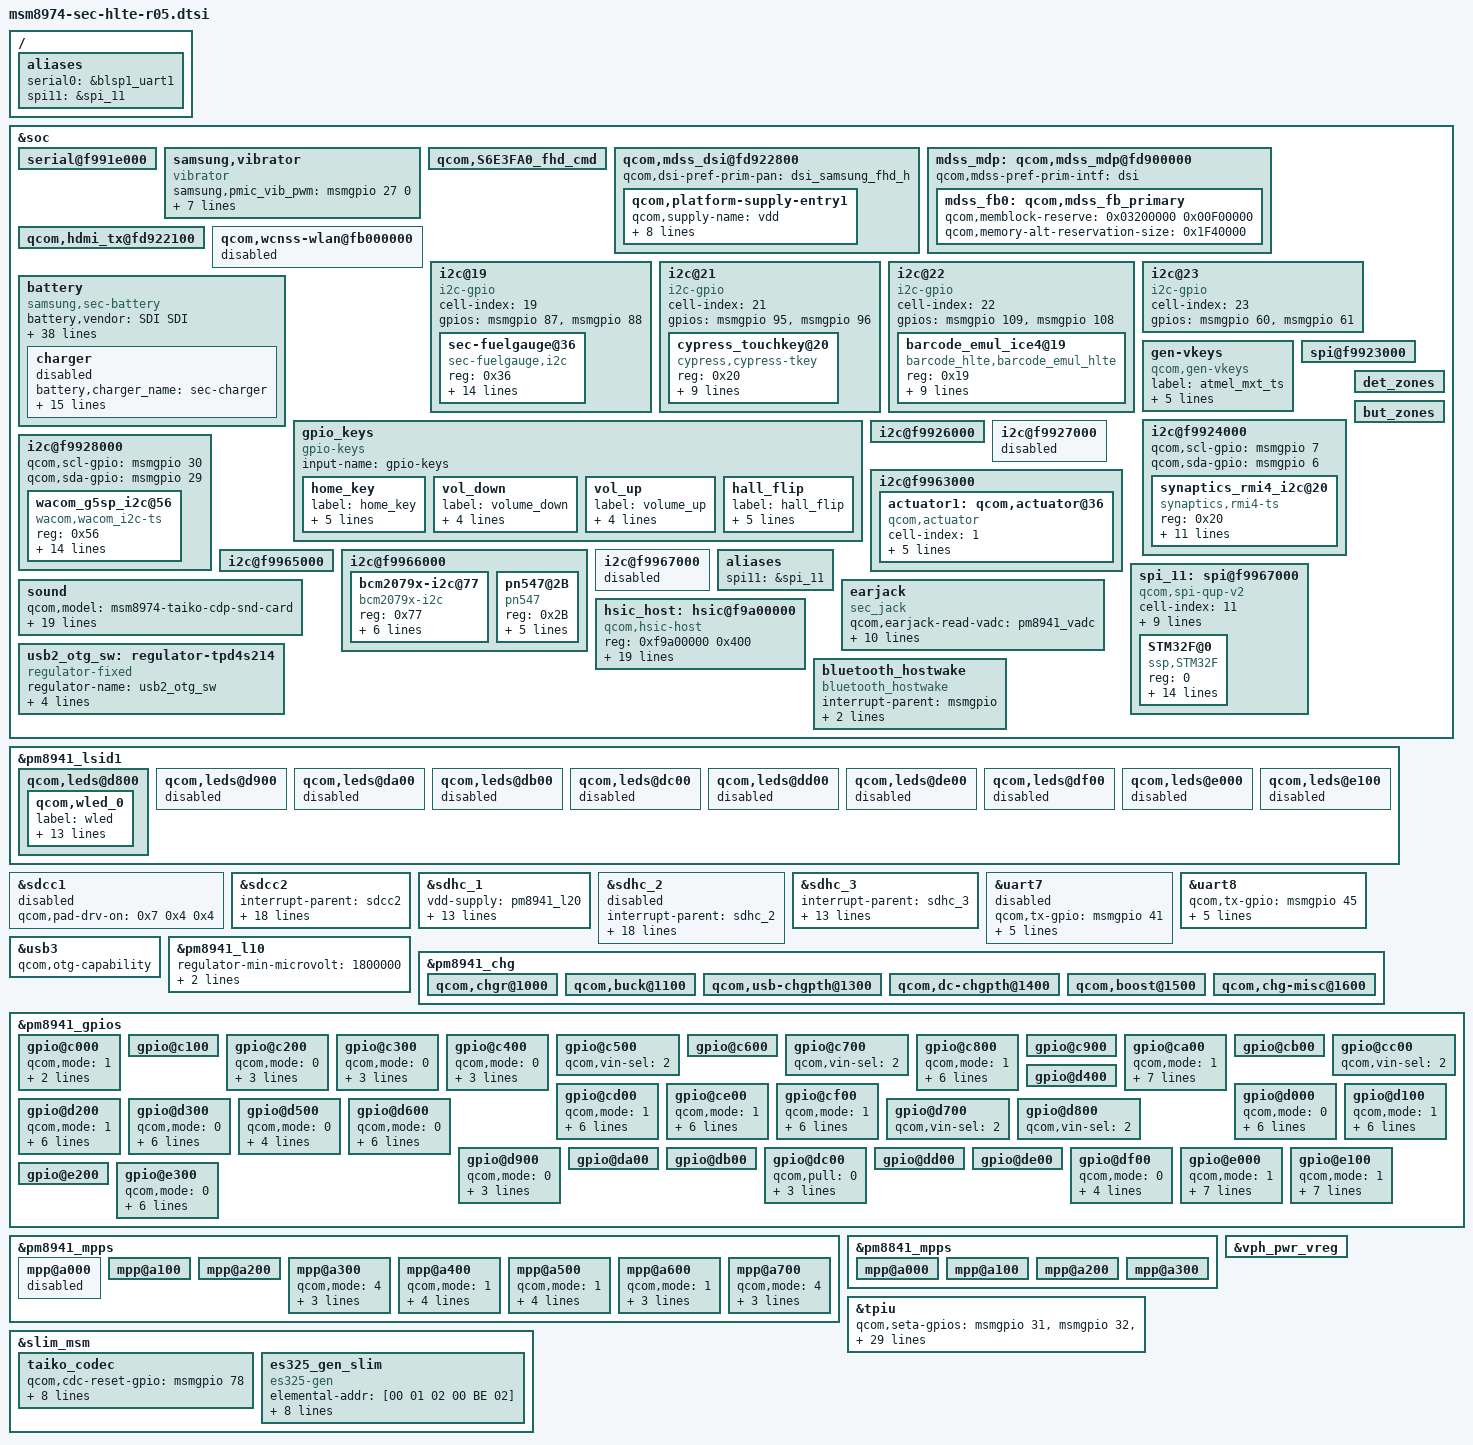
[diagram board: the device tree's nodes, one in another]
/* Copyright (c) 2012-2013, The Linux Foundation. All rights reserved.
 *
 * This program is free software; you can redistribute it and/or modify
 * it under the terms of the GNU General Public License version 2 and
 * only version 2 as published by the Free Software Foundation.
 *
 * This program is distributed in the hope that it will be useful,
 * but WITHOUT ANY WARRANTY; without even the implied warranty of
 * MERCHANTABILITY or FITNESS FOR A PARTICULAR PURPOSE.  See the
 * GNU General Public License for more details.
 */

/include/ "msm8974-leds.dtsi"
/include/ "msm8974-camera-sensor-hlte-r02.dtsi"
/include/ "msm8974-sii8240_mhl-hlte-r05.dtsi"
/include/ "msm8974-max77803-hlte-r02.dtsi"
/include/ "msm8974-w1.dtsi"

/ {
	aliases {
		serial0 = &blsp1_uart1;
		spi11 = &spi_11;
	};
};

&soc {
	serial@f991e000 {
		status = "ok";
	};

	samsung,vibrator {
		compatible = "vibrator";
		samsung,pmic_vib_pwm = <&msmgpio 27 0>;
		samsung,pmic_vib_pwm_jpn = <&msmgpio 59 0>;
		samsung,vib_model = <1>;
		samsung,pmic_vib_en = <0>;
		samsung,pmic_haptic_pwr_en = <0>;
		samsung,is_pmic_vib_pwm = <0>;
		samsung,pwm_period_us = <40>;
		samsung,duty_us = <36>;
		status = "ok";
	};
	qcom,S6E3FA0_fhd_cmd  {
		status = "ok";
	};

	qcom,mdss_dsi@fd922800 {
		qcom,dsi-pref-prim-pan = <&dsi_samsung_fhd_h>;
		qcom,platform-supply-entry1 {
				qcom,supply-name = "vdd";
				qcom,supply-min-voltage = <3000000>;
				qcom,supply-max-voltage = <3000000>;
				qcom,supply-enable-load = <100000>;
				qcom,supply-disable-load = <100>;
				qcom,supply-pre-on-sleep = <0>;
				qcom,supply-post-on-sleep = <20>;
				qcom,supply-pre-off-sleep = <0>;
				qcom,supply-post-off-sleep = <0>;
		};
	};

	mdss_mdp: qcom,mdss_mdp@fd900000 {
		qcom,mdss-pref-prim-intf = "dsi";
		mdss_fb0: qcom,mdss_fb_primary {
		    qcom,memblock-reserve = <0x03200000 0x00F00000>;
			qcom,memory-alt-reservation-size = <0x1F40000>;	 /* Framebuffer reservation only for LPM or recovery boot mode */
		};
	};

	qcom,hdmi_tx@fd922100 {
		status = "ok";
	};

	qcom,wcnss-wlan@fb000000 {
		status = "disabled";
	};

	i2c@19 {
		cell-index = <19>;
		compatible = "i2c-gpio";
		gpios = <&msmgpio 87 0 /* sda */
				&msmgpio 88 0 /* scl */
		>;
		#address-cells = <1>;
		#size-cells = <0>;

		sec-fuelgauge@36 {
			compatible = "sec-fuelgauge,i2c";
			reg = <0x36>;
			fuelgauge,fuel_int = <&pm8941_gpios 26 0x1>;
			fuelgauge,bat_int = <&pm8941_mpps 8 0>;

			fuelgauge,capacity_max = <1000>;
			fuelgauge,capacity_max_margin = <50>;
			fuelgauge,capacity_min = <0>;
			fuelgauge,capacity_calculation_type = <0x17>;
			fuelgauge,fuel_alert_soc = <2>;
			/* fuelgaguge,repeated_fuelalert; */
			fuelgauge,rcomp0 = <0x73>;
			fuelgauge,rcomp_charging = <0x8D>;
			fuelgauge,temp_cohot = <(-1000)>;
			fuelgauge,temp_cocold = <(-4325)>;
			fuelgauge,is_using_model_data;
			fuelgauge,type_str = "SDI";
			qcom,sec-fuelgauge-vadc = <&pm8941_vadc>;
		};
	};

	i2c@21 {
		cell-index = <21>;
		compatible = "i2c-gpio";
		gpios = <&msmgpio 95 0 /* sda */
		&msmgpio 96 0 /* scl */
		>;
		#address-cells = <1>;
		#size-cells = <0>;

		cypress_touchkey@20 {
			compatible = "cypress,cypress-tkey";
			reg = <0x20>;
			interrupt-parent = <&pm8941_gpios>;
			interrupts = <29 0>;
			vdd_led-supply = <&pm8941_l13>;
			vcc_en-supply = <&pm8941_lvs3>;
			cypress,scl-gpio = <&msmgpio 96 0x00>;
			cypress,sda-gpio = <&msmgpio 95 0x00>;
			cypress,irq-gpio = <&pm8941_gpios 29 0x1>;
			cypress,tkey-keycodes = <139 158>;
			cypress,i2c-pull-up = <1>;
		};
	};

	i2c@22 {
		cell-index = <22>;
		compatible = "i2c-gpio";
		gpios = <&msmgpio 109 0 /* sda */
		&msmgpio 108 0 /* scl */
		>;

		barcode_emul_ice4@19 {
			compatible = "barcode_hlte,barcode_emul_hlte";
			reg = <0x19>;
			interrupt-parent = <&pm8941_gpios>;
			interrupts = <27 0>;
			vdd-supply = <&pm8941_l19>;
			barcode,cresetb = <&pm8941_gpios 18 0x01>;
			barcode,reset_n = <&msmgpio 132 0x00>;
			barcode,scl-gpio = <&msmgpio 108 0x00>;
			barcode,sda-gpio = <&msmgpio 109 0x00>;
			barcode,irq-gpio = <&pm8941_gpios 27 0x00>;
			barcode,i2c-pull-up = <1>;
		};
	};

	i2c@23 {
		cell-index = <23>;
		compatible = "i2c-gpio";
		gpios = <&msmgpio 60 0 /* sda */
		&msmgpio 61 0 /* scl */
		>;
	};

	qcom,hdmi_tx@fd922100 {
		status = "ok";
	};

	battery {
		status = "okay";
		compatible = "samsung,sec-battery";
		battery,vendor = "SDI SDI";
		battery,charger_name = "sec-charger";
		battery,fuelgauge_name = "sec-fuelgauge";
		battery,technology = <2>; /* POWER_SUPPLY_TECHNOLOGY_LION */
		battery,bat_int = <&pm8941_mpps 8 0>;
		battery,bat_irq_attr = <0x3>;

		battery,chip_vendor = "QCOM";
		battery,temp_adc_type = <1>; /* SEC_BATTERY_ADC_TYPE_AP */

		battery,polling_time = <10 30 30 30 3600>;

		battery,adc_check_count = <6>;

		battery,cable_check_type = <4>; /* SEC_BATTERY_CABLE_CHECK_PSY */
		battery,cable_source_type = <1>; /* SEC_BATTERY_CABLE_SOURCE_EXTERNAL */
		battery,event_check;
		battery,event_waiting_time = <600>;
		battery,polling_type = <1>; /* SEC_BATTERY_MONITOR_ALARM */
		battery,monitor_initial_count = <3>;

		battery,battery_check_type = <6>; /* SEC_BATTERY_CHECK_INT */
		battery,check_count = <0>;
		battery,check_adc_max = <1440>;
		battery,check_adc_min = <0>;

		battery,ovp_uvlo_check_type = <3>; /* SEC_BATTERY_OVP_UVLO_CHGPOLLING */

		battery,thermal_source = <2>; /* SEC_BATTERY_THERMAL_SOURCE_ADC */

		battery,temp_check_type = <2>; /* _BATTERY_TEMP_CHECK_TEMP */
		battery,temp_check_count = <1>;
		battery,full_check_type = <7>; /* SEC_BATTERY_FULLCHARGED_CHGPSY */
		battery,full_check_type_2nd = <3>; /* SEC_BATTERY_FULLCHARGED_TIME */
		battery,full_check_count = <1>;
		battery,chg_gpio_full_check = <0>;
		battery,chg_polarity_full_check = <1>;

		/* SEC_BATTERY_FULL_CONDITION_SOC |
		   SEC_BATTERY_FULL_CONDITION_NOTIMEFULL |
		   SEC_BATTERY_FULL_CONDITION_VCELL */
		battery,full_condition_type = <13>;
		battery,full_condition_soc = <97>;
		battery,full_condition_vcell = <4250>;

		battery,recharge_check_count = <1>;
		battery,recharge_condition_type = <4>; /* SEC_BATTERY_RECHARGE_CONDITION_VCELL */
		battery,recharge_condition_soc = <98>;
		battery,recharge_condition_vcell = <4300>;

		battery,charging_total_time = <21600>;
		battery,recharging_total_time = <5400>;
		battery,charging_reset_time = <0>;

		charger{
			status = "disable";
			/* Charger */
			battery,charger_name = "sec-charger";
			battery,chg_gpio_en = <0>;
			battery,chg_polarity_en = <0>;
			battery,chg_gpio_status = <0>;
			battery,chg_polarity_status = <0>;
			battery,chg_float_voltage = <4350>;
			battery,ovp_uvlo_check_type = <3>; /* SEC_BATTERY_OVP_UVLO_CHGPOLLING */
			battery,full_check_type = <7>; /* SEC_BATTERY_FULLCHARGED_CHGPSY */

			battery,input_current_limit = <1800 460 460 1800 460 900 1000 460 460 1000 650 1800 1800 460 1300 300 700 1300 300 1000 1800 460 460>;
			battery,fast_charging_current = <2100 0 460 2100 460 1200 1000 460 0 1200 750 2100 2100 0 1300 300 700 1300 300 1000 2100 0 0>;
			battery,full_check_current_1st = <200 0 200 200 200 200 200 200 0 200 200 200 200 0 200 200 200 200 200 200 200 0 0>;
			battery,full_check_current_2nd = <2400 0 2400 2400 2400 2400 2400 2400 0 2400 2400 2400 2400 0 2400 2400 2400 2400 2400 2400 2400 0 0>;
		};
	};

	gen-vkeys {
		compatible = "qcom,gen-vkeys";
		label = "atmel_mxt_ts";
		qcom,disp-maxx = <720>;
		qcom,disp-maxy = <1280>;
		qcom,panel-maxx = <760>;
		qcom,panel-maxy = <1424>;
		qcom,key-codes = <158 139 102 217>;
	};

	gpio_keys {
		compatible = "gpio-keys";
		input-name = "gpio-keys";

		home_key {
			label = "home_key";
			gpios = <&pm8941_gpios 3 0x1>;
			linux,input-type = <1>;
			linux,code = <172>;
			gpio-key,wakeup;
			debounce-interval = <15>;
		};

		vol_down {
			label = "volume_down";
			gpios = <&pm8941_gpios 2 0x1>;
			linux,input-type = <1>;
			linux,code = <114>;
			debounce-interval = <15>;
		};

		vol_up {
			label = "volume_up";
			gpios = <&pm8941_gpios 5 0x1>;
			linux,input-type = <1>;
			linux,code = <115>;
			debounce-interval = <15>;
		};

		hall_flip {
			label = "hall_flip";
			gpios = <&pm8941_gpios 36 0>;
			linux,input-type = <1>;
			linux,code = <0x0>;
			gpio-key,wakeup;
			debounce-interval = <15>;
		};
	};

	/* BLSP#1 */
	spi@f9923000 {
		status = "okay";
	};

	/* BLSP#2 */
	i2c@f9924000 {
		qcom,scl-gpio = <&msmgpio 7 0>;
		qcom,sda-gpio = <&msmgpio 6 0>;
		status = "okay";

		synaptics_rmi4_i2c@20 {
			compatible = "synaptics,rmi4-ts";
			reg = <0x20>;
			interrupt-parent = <&pm8941_gpios>;
			interrupts = <30 0>;
			vcc_en-supply = <&pm8941_l10>;
			synaptics,supply-num = <1>;		/* the number of regulators */
			synaptics,supply-name = "8941_l10";	/* the name of regulators, in power-on order */
			synaptics,external_ldo = <&pm8941_gpios 9 0x1>;
			synaptics,irq-gpio = <&pm8941_gpios 30 0x1>;
			synaptics,tsp-coords = <1079 1919>;
			synaptics,i2c-pull-up = <1>;
			synaptics,tsp-project = "H";
			synaptics,tsp-extra_config = <0 0 0 0>;/* <"pwrctrl", "N", "N", "N"> */
		};
	};

	/* BLSP#3 */
	/* i2c@f9925000 {
	}; */

	/* BLSP#4 */
	i2c@f9926000 {
		status = "okay";
	};

	/* BLSP#5 */
	/* spi_5: spi@f9927000 {
		status = "disabled";
	};*/

	i2c@f9927000 {
		status = "disabled";
	};

	/* BLSP#6 */
	i2c@f9928000 {
		qcom,scl-gpio = <&msmgpio 30 0>;
		qcom,sda-gpio = <&msmgpio 29 0>;
		status = "okay";

		wacom_g5sp_i2c@56 {
			compatible = "wacom,wacom_i2c-ts";
			reg = <0x56>;
			interrupt-parent = <&msmgpio>;
			interrupts = <144 0>;
			vdd_en-gpio = <&pm8941_gpios 35 0x1>;
			wacom,reset_n-gpio = <&msmgpio 79 0x00>;
			wacom,pen_fwe1-gpio = <&msmgpio 80 0x00>;
			wacom,pen_pdct-gpio = <&msmgpio 145 0x00>;
			wacom,sense-gpio = <&pm8941_gpios 20 0x1>;
			wacom,irq-gpio = <&msmgpio 144 0x00>;
			wacom,panel-coords = <1 0 0 12576 0 7074 1 0 1023>;
			wacom,i2c-pull-up = <1>;
			wacom,basic_model = "SM-N9005";
			wacom,ic_mpu_ver = <0x2C>;
			wacom,irq_flags = <0x2>;
		};
	};

	/* BLSP#7 */
	 i2c@f9963000 {
		actuator1: qcom,actuator@36 {
		compatible = "qcom,actuator";
		cell-index = <1>;
		reg = <0x36>;
			gpios = <&msmgpio 43 0>,
				<&msmgpio 44 0>;
			qcom,gpio-req-tbl-num = <0 1>;
			qcom,gpio-req-tbl-flags = <1 1>;
			qcom,gpio-req-tbl-label = "I2C_DATA0",
						  "I2C_CLK0";
		};
	};

	/* BLSP#8 */
	/* i2c@f9964000 {
	}; */

	/* BLSP#9 */
	i2c@f9965000 {
		status = "okay";
	};

	/* BLSP#10 */
	i2c@f9966000 {
		status = "okay";
		bcm2079x-i2c@77 {
			compatible = "bcm2079x-i2c";
			reg = <0x77>;
			interrupt-parent = <&msmgpio>;
			interrupts = <59 0>;
			bcm2079x-i2c,irq-gpio = <&msmgpio 59 0x00>;
			bcm2079x-i2c,en-gpio = <&pm8941_gpios 13 0x1>;
			bcm2079x-i2c,wake-gpio = <&msmgpio 63 0x00>;
			bcm2079x-i2c,ap-rev = <5>;
		};
		pn547@2B {
			compatible = "pn547";
			reg = <0x2B>;
			interrupt-parent = <&msmgpio>;
			interrupts = <59 0>;
			pn547,irq-gpio = <&msmgpio 59 0x00>;
			pn547,ven-gpio = <&pm8941_gpios 13 0x1>;
			pn547,firm-gpio = <&msmgpio 63 0x00>;
		};
	};

	/* BLSP#11 */
	i2c@f9967000 {
		status = "disabled";
	};

	aliases {
		spi11 = &spi_11;
	};

	spi_11: spi@f9967000 {
		compatible = "qcom,spi-qup-v2";
		cell-index = <11>;
		#address-cells = <1>;
		#size-cells = <0>;
		reg = <0xf9967000 0x1000>;
		interrupt-names = "spi_irq";
		interrupts = <0 105 0>;
		spi-max-frequency = <4800000>;
		spi-cpha;
		qcom,gpio-mosi = <&msmgpio 81 0>;
		qcom,gpio-miso = <&msmgpio 82 0>;
		qcom,gpio-clk  = <&msmgpio 84 0>;
		qcom,gpio-cs0  = <&msmgpio 83 0>;
		qcom,master-id = <84>;
		STM32F@0 {
			compatible = "ssp,STM32F";
			reg = <0>;
			spi-max-frequency = <4800000>;
			interrupt-parent = <&msmgpio>;
			interrupts = <74 0>;
			hub_vreg-supply = <&pm8941_lvs1>;
			psns_vreg-supply = <&pm8941_l18>;
			ssp,mcu_int1-gpio = <&msmgpio 74 0x00>;
			ssp,mcu_int2-gpio = <&msmgpio 86 0x00>;
			ssp,ap_int-gpio = <&msmgpio 89 0x00>;
			ssp,rst-gpio = <&msmgpio 50 0x00>;
			ssp,acc-position = <6>;
			ssp,mag-position = <3>;
			ssp,sns-combination = <0>;
			ssp,ap-rev=<5>;
			qcom,temphumidity_sensor-vadc = <&pm8941_vadc>;
		};
	};

	sound {
		qcom,model = "msm8974-taiko-cdp-snd-card";
		qcom,hdmi-audio-rx;
		qcom,micbias-en-msm-gpio = <&pm8941_gpios 33 0>;

		qcom,audio-routing =
			"RX_BIAS", "MCLK",
			"LDO_H", "MCLK",
			"AIF4 MAD", "MCLK",
			"AMIC1", "Main Mic Bias",
			"Main Mic Bias", "Main Mic",
			"AMIC2", "MIC BIAS2 External",
			"MIC BIAS2 External", "Headset Mic",
			"AMIC3", "MIC BIAS1 External",
			"MIC BIAS1 External", "Sub Mic",
			"AMIC4", "MIC BIAS3 External",
			"MIC BIAS3 External", "Third Mic",
			"DMIC1", "MIC BIAS1 External",
			"MIC BIAS1 External", "Digital Mic1",
			"DMIC2", "MIC BIAS1 External",
			"MIC BIAS1 External", "Digital Mic2",
			"DMIC3", "MIC BIAS3 External",
			"MIC BIAS3 External", "Digital Mic3",
			"DMIC4", "MIC BIAS3 External",
			"MIC BIAS3 External", "Digital Mic4",
			"DMIC5", "MIC BIAS4 External",
			"MIC BIAS4 External", "Digital Mic5",
			"DMIC6", "MIC BIAS4 External",
			"MIC BIAS4 External", "Digital Mic6";
	};

	det_zones: det_zones {
		#list-det-cells = <4>;
	};

	but_zones: but_zones {
		#list-but-cells = <3>;
	};

	earjack {
		compatible = "sec_jack";
		qcom,earjack-read-vadc = <&pm8941_vadc>;
		qcom,earjack-detect-gpio = <&pm8941_gpios 22 0>;
		qcom,earjack-micbias-gpio = <&pm8941_gpios 34 0>;
		qcom,earjack-sendend-gpio = <&msmgpio 77 0>;

		det-zones-list = <&det_zones 3 10000 10 0>,
						 <&det_zones 936 10000 10 0>,
						 <&det_zones 2400 10000 10 1>,
						 <&det_zones 9999 10000 10 1>;
		but-zones-list = <&but_zones 0 0 162>,
						 <&but_zones 1 163 325>,
						 <&but_zones 2 326 645>;
		mpp-channel-scaling = <4 1 3>;
	};

	usb2_otg_sw: regulator-tpd4s214 {
		compatible = "regulator-fixed";
		regulator-name = "usb2_otg_sw";
		gpio = <&pm8941_gpios 18 0>;
		parent-supply = <&pm8941_boost>;
		startup-delay-us = <17000>;
		enable-active-high;
	};

	hsic_host: hsic@f9a00000 {
		compatible = "qcom,hsic-host";
		reg = <0xf9a00000 0x400>;
		#address-cells = <0>;
		interrupt-parent = <&hsic_host>;
		interrupts = <0 1 2>;
		#interrupt-cells = <1>;
		interrupt-map-mask = <0xffffffff>;
		interrupt-map = <0 &intc 0 136 0
			1 &intc 0 148 0
			2 &msmgpio 144 0x8>;
		interrupt-names = "core_irq", "async_irq", "wakeup";
		HSIC_VDDCX-supply = <&pm8841_s2>;
		HSIC_GDSC-supply = <&gdsc_usb_hsic>;
		hsic,strobe-gpio = <&msmgpio 144 0x00>;
		hsic,data-gpio = <&msmgpio 145 0x00>;
		hsic,resume-gpio = <&msmgpio 80 0x00>;
		hsic,ignore-cal-pad-config;
		hsic,strobe-pad-offset = <0x2050>;
		hsic,data-pad-offset = <0x2054>;
		qcom,phy-susp-sof-workaround;

		qcom,msm-bus,name = "hsic";
		qcom,msm-bus,num-cases = <2>;
		qcom,msm-bus,num-paths = <1>;
		qcom,msm-bus,vectors-KBps =
				<85 512 0 0>,
				<85 512 40000 160000>;
        };

	/* wlan0: qca,wlan {
		compatible = "qca,ar6004-hsic";
		qcom,msm-bus,name = "wlan";
		qcom,msm-bus,num-cases = <5>;
		qcom,msm-bus,active-only = <0>;
		qcom,msm-bus,num-paths = <1>;
		qcom,msm-bus,vectors-KBps =
				<85 512 0 0>,
				<85 512 40000 160000>,
				<85 512 40000 320000>,
				<85 512 40000 480000>,
				<85 512 40000 800000>;
	};*/

	bluetooth_hostwake{
		compatible = "bluetooth_hostwake";
		interrupt-parent = <&msmgpio>;
		interrupts = <75 0>;
		bluetooth_hostwake,irq-gpio = <&msmgpio 75 0x00>;
	};

};

&pm8941_lsid1 {
	qcom,leds@d800 {
		status = "okay";
		qcom,wled_0 {
			label = "wled";
			linux,name = "wled:backlight";
			linux,default-trigger = "bkl-trigger";
			qcom,cs-out-en;
			qcom,op-fdbck = <1>;
			qcom,default-state = "on";
			qcom,max-current = <25>;
			qcom,ctrl-delay-us = <0>;
			qcom,boost-curr-lim = <5>;
			qcom,cp-sel = <0>;
			qcom,switch-freq = <11>;
			qcom,ovp-val = <2>;
			qcom,num-strings = <3>;
			qcom,id = <0>;
		};
	};

	qcom,leds@d900 {
		status = "disabled";
	};

	qcom,leds@da00 {
		status = "disabled";
	};

	qcom,leds@db00 {
		status = "disabled";
	};

	qcom,leds@dc00 {
		status = "disabled";
	};

	qcom,leds@dd00 {
		status = "disabled";
	};

	qcom,leds@de00 {
		status = "disabled";
	};

	qcom,leds@df00 {
		status = "disabled";
	};

	qcom,leds@e000 {
		status = "disabled";
	};

	qcom,leds@e100 {
		status = "disabled";
	};
};

&sdcc1 {
       status = "disabled";
};

&sdcc2 {
	#address-cells = <0>;
	interrupt-parent = <&sdcc2>;
	interrupts = <0 1>;
	#interrupt-cells = <1>;
	interrupt-map-mask = <0xffffffff>;
	interrupt-map = <0 &intc 0 125 0
					1 &intc 0 220 0>;
	interrupt-names = "core_irq", "bam_irq";
	//cd-gpios = <&msmgpio 62 0x1>;
	wp-gpios = <&pm8941_gpios 29 0x1>;

	vdd-supply = <&pm8941_s3>;
	vdd-io-supply = <&pm8941_s3>;

	qcom,vdd-always-on;
	qcom,vdd-voltage-level = <1800000 1800000>;
	qcom,vdd-current-level = <2000 16000>;

	qcom,vdd-io-always-on;
	qcom,vdd-io-voltage-level = <1800000 1800000>;
	qcom,vdd-io-current-level = <2000 16000>;

	qcom,current-limit = <16000>;

	qcom,clk-rates = <400000 20000000 25000000 50000000 100000000 200000000>;
	qcom,sup-voltages = <2950 2950>;

	status-cb = <2>;
	status = "ok";
};

&sdhc_1 {
	vdd-supply = <&pm8941_l20>;
	vdd-io-supply = <&pm8941_s3>;

	qcom,vdd-always-on;
	qcom,vdd-lpm-sup;
	qcom,vdd-voltage-level = <2950000 2950000>;
	qcom,vdd-current-level = <800 500000>;

	qcom,vdd-io-always-on;
	qcom,vdd-io-voltage-level = <1800000 1800000>;
	qcom,vdd-io-current-level = <250 154000>;

	qcom,pad-pull-on = <0x0 0x3 0x3>; /* no-pull, pull-up, pull-up */
	qcom,pad-pull-off = <0x0 0x3 0x3>; /* no-pull, pull-up, pull-up */
	qcom,pad-drv-on = <0x7 0x4 0x4>; /* 16mA, 10mA, 10mA */
	qcom,pad-drv-off = <0x0 0x0 0x0>; /* 2mA, 2mA, 2mA */

	qcom,nonremovable;
	status = "ok";
};

&sdhc_2 {
	#address-cells = <0>;
	interrupt-parent = <&sdhc_2>;
	interrupts = <0 1>;
	#interrupt-cells = <1>;
	interrupt-map-mask = <0xffffffff>;
	interrupt-map = <0 &intc 0 125 0
			1 &intc 0 221 0>;
	interrupt-names = "hc_irq", "pwr_irq";
	//cd-gpios = <&msmgpio 62 0x1>;

	vdd-supply = <&pm8941_l21>;
	vdd-io-supply = <&pm8941_l21>;

	qcom,vdd-voltage-level = <2950000 2950000>;
	qcom,vdd-current-level = <9000 800000>;

	qcom,vdd-io-voltage-level = <1800000 2950000>;
	qcom,vdd-io-current-level = <6 22000>;

	qcom,pad-pull-on = <0x0 0x3 0x3>; /* no-pull, pull-up, pull-up */
	qcom,pad-pull-off = <0x0 0x3 0x3>; /* no-pull, pull-up, pull-up */
	qcom,pad-drv-on = <0x7 0x4 0x4>; /* 16mA, 10mA, 10mA */
	qcom,pad-drv-off = <0x0 0x0 0x0>; /* 2mA, 2mA, 2mA */

	qcom,current-limit = <16000>;

	qcom,clk-rates = <400000 20000000 25000000 50000000 100000000 200000000>;

	qcom,sup-voltages = <2950 2950>;

	status-cb = <2>;
	status = "disabled";
};

&sdhc_3 {
	#address-cells = <0>;
	interrupt-parent = <&sdhc_3>;
	interrupts = <0 1 2>;
	#interrupt-cells = <1>;
	interrupt-map-mask = <0xffffffff>;
	interrupt-map = <0 &intc 0 127 0
			1 &intc 0 224 0
			2 &msmgpio 62 0x3>;
	interrupt-names = "hc_irq", "pwr_irq", "status_irq";

	vdd-supply = <&pm8941_l21>;
	vdd-io-supply = <&pm8941_l21>;
	qcom,vdd-voltage-level = <2950000 2950000>;
	qcom,vdd-current-level = <9000 800000>;
	qcom,vdd-io-voltage-level = <2950000 2950000>;
	qcom,vdd-io-current-level = <6 22000>;
	qcom,sup-voltages = <2950 2950>;

	cd-gpios = <&msmgpio 62 0x1>;
	wp-gpios = <&pm8941_gpios 29 0x1>;

	status = "ok";
};

/* Drive strength recommendations for clock line from hardware team is 10 mA.
 * But since the driver has been been using the below values from the start
 * without any problems, continue to use those.
 */
&sdcc1 {
	qcom,pad-drv-on = <0x7 0x4 0x4>; /* 16mA, 10mA, 10mA */
};

&sdcc2 {
	qcom,pad-drv-on = <0x7 0x4 0x4>; /* 16mA, 10mA, 10mA */
};

&sdhc_1 {
	qcom,pad-drv-on = <0x7 0x4 0x4>; /* 16mA, 10mA, 10mA */
};

&sdhc_2 {
	qcom,pad-drv-on = <0x7 0x4 0x4>; /* 16mA, 10mA, 10mA */
};

&uart7 {
	status = "disabled";
	qcom,tx-gpio = <&msmgpio 41 0x00>;
	qcom,rx-gpio = <&msmgpio 42 0x00>;
	qcom,cts-gpio = <&msmgpio 8 0x00>;
	qcom,rfr-gpio = <&msmgpio 44 0x00>;
	qcom,inject-rx-on-wakeup = <1>;
	qcom,rx-char-to-inject = <0xFD>;
};

&uart8 {
	status = "ok";
	qcom,tx-gpio = <&msmgpio 45 0x00>;
	qcom,rx-gpio = <&msmgpio 46 0x00>;
	qcom,cts-gpio = <&msmgpio 47 0x00>;
	qcom,rfr-gpio = <&msmgpio 48 0x00>;
	qcom,inject-rx-on-wakeup = <1>;
	qcom,rx-char-to-inject = <0xFD>;
};

&usb3 {
	qcom,otg-capability;
};

&pm8941_l10 {
	regulator-min-microvolt = <1800000>;
	regulator-max-microvolt = <1800000>;
	qcom,init-voltage = <1800000>;
};

&pm8941_chg {
	status = "ok";

	qcom,chgr@1000 {
		status = "ok";
	};

	qcom,buck@1100 {
		status = "ok";
	};

	qcom,usb-chgpth@1300 {
		status = "ok";
	};

	qcom,dc-chgpth@1400 {
		status = "ok";
	};

	qcom,boost@1500 {
		status = "ok";
	};

	qcom,chg-misc@1600 {
		status = "ok";
	};
};

&pm8941_gpios {
	gpio@c000 { /* GPIO 1 */
		/* CAM_MOVIE_EN pin */
		qcom,mode = <1>;	/* DIG_OUT */
		qcom,pull = <4>;	/* QPNP_PIN_PULL_DOWN */
		qcom,vin-sel = <2>;		/* PM8941 S3 = 1.8 V */
	};

	gpio@c100 { /* GPIO 2 */
	};

	gpio@c200 { /* GPIO 3 */
		qcom,mode = <0>;
		qcom,pull = <0>;
		qcom,vin-sel = <2>;
		qcom,src-sel = <0>;
	};

	gpio@c300 { /* GPIO 4 */
		qcom,mode = <0>;
		qcom,pull = <0>;
		qcom,vin-sel = <2>;
		qcom,src-sel = <0>;
	};

	gpio@c400 { /* GPIO 5 */
		qcom,mode = <0>;
		qcom,pull = <0>;
		qcom,vin-sel = <2>;
		qcom,src-sel = <0>;
	};

	gpio@c500 { /* GPIO 6 */
		qcom,vin-sel = <2>;		/* PM8941 S3 = 1.8 V */
	};

	gpio@c600 { /* GPIO 7 */
	};

	gpio@c700 { /* GPIO 8 */
		qcom,vin-sel = <2>;		/* PM8941 S3 = 1.8 V */
	};

	gpio@c800 { /* GPIO 9 */
		qcom,mode = <1>;  /* QPNP_PIN_MODE_DIG_OUT */
		qcom,output-type = <0>; /* QPNP_PIN_OUT_BUF_CMOS */
		qcom,pull = <5>; /* QPNP_PIN_PULL_NO */
		qcom,vin-sel = <2>; /* QPNP_PIN_VIN2 */
		qcom,out-strength = <3>; /* QPNP_PIN_OUT_STRENGTH_HIGH */
		qcom,src-sel = <0>; /* QPNP_PIN_SEL_FUNC_CONSTANT */
		qcom,master-en = <1>;
	};

	gpio@c900 { /* GPIO 10 */
	};

	gpio@ca00 { /* GPIO 11 */
		qcom,mode = <1>;		/* Digital output */
		qcom,output-type = <0>;	/* CMOS logic */
		qcom,pull = <5>;			/* QPNP_PIN_PULL_NO */
		qcom,invert = <1>;		/* Output low initially */
		qcom,vin-sel = <2>;		/* PM8941 S3 = 1.8 V */
		qcom,src-sel = <0>;		/* Constant */
		qcom,out-strength = <2>;	/* Medium drive strength */
		qcom,master-en = <1>;	/* Enable GPIO */
	};

	gpio@cb00 { /* GPIO 12 */
	};

	gpio@cc00 { /* GPIO 13 */
		qcom,vin-sel = <2>;
	};

	gpio@cd00 { /* GPIO 14 */
		qcom,mode = <1>;  /* QPNP_PIN_MODE_DIG_OUT */
		qcom,output-type = <0>; /* QPNP_PIN_OUT_BUF_CMOS */
		qcom,pull = <5>; /* QPNP_PIN_PULL_NO */
		qcom,vin-sel = <2>; /* QPNP_PIN_VIN2 */
		qcom,out-strength = <3>; /* QPNP_PIN_OUT_STRENGTH_HIGH */
		qcom,src-sel = <0>; /* QPNP_PIN_SEL_FUNC_CONSTANT */
		qcom,master-en = <1>;
	};

	gpio@ce00 { /* GPIO 15 */
		qcom,mode = <1>;
		qcom,output-type = <0>;
		qcom,pull = <5>;
		qcom,vin-sel = <2>;
		qcom,out-strength = <1>;
		qcom,src-sel = <2>;
		qcom,master-en = <1>;
	};

	gpio@cf00 { /* GPIO 16 used for BT sleep_clk*/
		qcom,mode = <1>;
		qcom,output-type = <0>;
		qcom,pull = <5>;
		qcom,out-strength = <3>;
		qcom,vin-sel = <2>;
		qcom,src-sel = <3>;
		qcom,master_en = <1>;
	};

	gpio@d000 { /* GPIO 17 */
		qcom,mode = <0>;		/* QPNP_PIN_MODE_DIG_IN */
		qcom,output-type = <0>;		/* QPNP_PIN_OUT_BUF_CMOS */
		qcom,pull = <5>;		/* QPNP_PIN_PULL_NO */
		qcom,vin-sel = <2>; 		/* QPNP_PIN_VIN2 */
		qcom,out-strength = <3>;	/* QPNP_PIN_OUT_STRENGTH_HIGH */
		qcom,src-sel = <0>;		/* QPNP_PIN_SEL_FUNC_2 : LPG8*/
		qcom,master-en = <1>;
	};

	gpio@d100 { /* GPIO 18 */
		/* usb2_otg_sw regulator enable */
		qcom,mode = <1>;		/* Digital output */
		qcom,output-type = <0>;		/* CMOS logic */
		qcom,invert = <0>;		/* Output low initially */
		qcom,vin-sel = <2>;		/* PM8941 S3 = 1.8 V */
		qcom,src-sel = <0>;		/* Constant */
		qcom,out-strength = <2>;	/* Medium drive strength */
		qcom,master-en = <1>;		/* Enable GPIO */
	};

	gpio@d200 { /* GPIO 19 */
		qcom,mode = <1>;		/* QPNP_PIN_MODE_DIG_OUT */
		qcom,output-type = <0>;		/* QPNP_PIN_OUT_BUF_CMOS */
		qcom,pull = <5>;		/* QPNP_PIN_PULL_NO */
		qcom,vin-sel = <2>;		/* QPNP_PIN_VIN2 */
		qcom,out-strength = <2>;	/* QPNP_PIN_OUT_STRENGTH_MED */
		qcom,src-sel = <0>;		/* QPNP_PIN_SEL_FUNC_CONSTANT */
		qcom,master-en = <1>;
	};

	gpio@d300 { /* GPIO 20 */
		qcom,mode = <0>;		/* QPNP_PIN_MODE_DIG_IN */
		qcom,output-type = <0>;		/* QPNP_PIN_OUT_BUF_CMOS */
		qcom,pull = <5>;		/* QPNP_PIN_PULL_NO */
		qcom,vin-sel = <2>;		/* QPNP_PIN_VIN2 */
		qcom,out-strength = <2>;	/* QPNP_PIN_OUT_STRENGTH_MED */
		qcom,src-sel = <0>;		/* QPNP_PIN_SEL_FUNC_CONSTANT */
		qcom,master-en = <1>;
	};

	gpio@d400 { /* GPIO 21 */
	};

	gpio@d500 { /* GPIO 22 */
		qcom,mode = <0>;	/* input */
		qcom,pull = <5>;		/* pull-up with 30uA current strength */
		qcom,vin-sel = <2>;	/* VIN=S3 */
		qcom,src-sel = <0>;	/* constant */
		qcom,master_en = <1>;
	};

	gpio@d600 { /* GPIO 23 */
		qcom,mode = <0>;		/* QPNP_PIN_MODE_DIG_IN */
		qcom,output-type = <0>;		/* QPNP_PIN_OUT_BUF_CMOS */
		qcom,pull = <5>;		/* QPNP_PIN_PULL_NO */
		qcom,vin-sel = <2>;		/* QPNP_PIN_VIN2 */
		qcom,out-strength = <3>;	/* QPNP_PIN_OUT_STRENGTH_HIGH */
		qcom,src-sel = <0>;		/* QPNP_PIN_SEL_FUNC_CONSTANT*/
		qcom,master-en = <1>;
	};

	gpio@d700 { /* GPIO 24 */
		/* VT sensor rst pin */
		qcom,vin-sel = <2>;		/* PM8941 S3 = 1.8 V */
	};

	gpio@d800 { /* GPIO 25 */
		/* 8M sensor rst pin */
		qcom,vin-sel = <2>;		/* PM8941 S3 = 1.8 V */
	};

	gpio@d900 { /* GPIO 26 */
		qcom,mode = <0>;		/* QPNP_PIN_MODE_DIG_IN */
		qcom,pull = <5>;		/* QPNP_PIN_PULL_NO */
		qcom,vin-sel = <2>;		/* QPNP_PIN_VIN2 */
		qcom,src-sel = <0>;		/* QPNP_PIN_SEL_FUNC_CONSTANT */
	};

	gpio@da00 { /* GPIO 27 */
	};

	gpio@db00 { /* GPIO 28 */
	};

	gpio@dc00 { /* GPIO 29 */
		qcom,pull = <0>; /* set to default pull */
		qcom,master-en = <1>;
		qcom,vin-sel = <2>; /* select 1.8 V source */
		qcom,src-sel = <3>;
	};

	gpio@dd00 { /* GPIO 30 */
	};

	gpio@de00 { /* GPIO 31 */
	};

	gpio@df00 { /* GPIO 32 */
		status = "ok";
		qcom,mode = <0>;
		qcom,pull = <4>;
		qcom,src-sel = <0>;
		qcom,vin-sel = <2>;
		qcom,master-en = <1>;
	};

	gpio@e000 { /* GPIO 33 */
		qcom,mode = <1>;		/* Digital output */
		qcom,output-type = <0>;	/* CMOS logic */
		qcom,pull = <5>;			/* QPNP_PIN_PULL_NO */
		qcom,invert = <0>;		/* Output low initially */
		qcom,vin-sel = <2>;		/* PM8941 S3 = 1.8 V */
		qcom,src-sel = <0>;		/* Constant */
		qcom,out-strength = <2>;	/* Medium drive strength */
		qcom,master-en = <1>;	/* Enable GPIO */
	};

	gpio@e100 { /* GPIO 34 */
		qcom,mode = <1>;		/* Digital output */
		qcom,output-type = <0>;	/* CMOS logic */
		qcom,pull = <5>;			/* QPNP_PIN_PULL_NO */
		qcom,invert = <0>;		/* Output low initially */
		qcom,vin-sel = <2>;		/* PM8941 S3 = 1.8 V */
		qcom,src-sel = <0>;		/* Constant */
		qcom,out-strength = <2>;	/* Medium drive strength */
		qcom,master-en = <1>;	/* Enable GPIO */
	};

	gpio@e200 { /* GPIO 35 */
	};

	gpio@e300 { /* GPIO 36 */
		qcom,mode = <0>;
		qcom,output-type = <0>;
		qcom,vin-sel = <2>;
		qcom,out-strength = <2>;
		qcom,src-sel = <3>;
		qcom,pull = <5>;
		qcom,master-en = <1>;
	};
};

&pm8941_mpps {

	mpp@a000 { /* MPP 1 */
		status = "disabled";
	};

	mpp@a100 { /* MPP 2 */
	};

	mpp@a200 { /* MPP 3 */
	};

	mpp@a300 { /* MPP 4 */
		qcom,mode = <4>; /* AIN input */
		qcom,ain-route = <3>; /* AMUX 8 */
		qcom,master-en = <1>;/* Enable MPP4 */
		qcom,src-sel = <0>; /* Function constant */
	};

	mpp@a400 { /* MPP 5 */
		qcom,mode = <1>; /* DIG_OUT */
		qcom,output-type = <0>; /* CMOS */
		qcom,vin-sel = <2>; /* PM8941_S3 1.8V > 1.6V */
		qcom,src-sel = <0>; /* CONSTANT */
		qcom,master-en = <1>; /* ENABLE MPP */
	};

	mpp@a500 { /* MPP 6 */
		/* SPI_ETH_RST config */
		qcom,mode = <1>; /* DIG_OUT */
		qcom,output-type = <0>; /* CMOS */
		qcom,vin-sel = <2>; /* PM8941_S3 1.8V > 1.6V */
		qcom,src-sel = <0>; /* CONSTANT */
		qcom,master-en = <1>; /* ENABLE MPP */
	};

	mpp@a600 { /* MPP 7 */
		/* CAM_FLASH_EN pin */
		qcom,mode = <1>; 		/* DIG_OUT */
		qcom,vin-sel = <2>;		/* S3A 1.8v */
		qcom,src-sel = <0>;		/* CONSTANT */
		qcom,master-en = <1>;	/* ENABLE MPP */
	};

	mpp@a700 { /* MPP 8 */
		qcom,mode = <4>; /* AIN input */
		qcom,ain-route = <3>; /* AMUX 8 */
		qcom,master-en = <1>;/* Enable MPP4 */
		qcom,src-sel = <0>; /* Function constant */
	};
};

&pm8841_mpps {

	mpp@a000 { /* MPP 1 */
	};

	mpp@a100 { /* MPP 2 */
	};

	mpp@a200 { /* MPP 3 */
	};

	mpp@a300 { /* MPP 4 */
	};
};

/* CoreSight */
&tpiu {
	qcom,seta-gpios = <&msmgpio 31 0>,
			  <&msmgpio 32 0>,
			  <&msmgpio 33 0>,
			  <&msmgpio 34 0>,
			  <&msmgpio 35 0>,
			  <&msmgpio 36 0>,
			  <&msmgpio 37 0>,
			  <&msmgpio 38 0>,
			  <&msmgpio 39 0>,
			  <&msmgpio 40 0>,
			  <&msmgpio 41 0>,
			  <&msmgpio 42 0>,
			  <&msmgpio 43 0>,
			  <&msmgpio 44 0>,
			  <&msmgpio 45 0>,
			  <&msmgpio 46 0>,
			  <&msmgpio 47 0>,
			  <&msmgpio 48 0>;
	qcom,seta-gpios-func = <4 4 4 3 4 4 4 3 4 3 5 5 5 5 4 4 5 5>;
	qcom,seta-gpios-drv =  <7 7 7 7 7 7 7 7 7 7 7 7 7 7 7 7 7 7>;
	qcom,seta-gpios-pull = <0 0 0 0 0 0 0 0 0 0 0 0 0 0 0 0 0 0>;
	qcom,seta-gpios-dir =  <2 2 2 2 2 2 2 2 2 2 2 2 2 2 2 2 2 2>;

	qcom,setb-gpios = <&msmgpio 15 0>,
			  <&msmgpio 16 0>,
			  <&msmgpio 17 0>,
			  <&msmgpio 18 0>,
			  <&msmgpio 19 0>,
			  <&msmgpio 20 0>,
			  <&msmgpio 21 0>,
			  <&msmgpio 22 0>,
			  <&msmgpio 23 0>,
			  <&msmgpio 24 0>,
			  <&msmgpio 25 0>,
			  <&msmgpio 26 0>,
			  <&msmgpio 27 0>,
			  <&msmgpio 28 0>,
			  <&msmgpio 89 0>,
			  <&msmgpio 90 0>,
			  <&msmgpio 91 0>,
			  <&msmgpio 92 0>;
	qcom,setb-gpios-func = <2 2 2 2 5 5 5 5 6 6 6 7 7 5 2 3 3 3>;
	qcom,setb-gpios-drv =  <7 7 7 7 7 7 7 7 7 7 7 7 7 7 7 7 7 7>;
	qcom,setb-gpios-pull = <0 0 0 0 0 0 0 0 0 0 0 0 0 0 0 0 0 0>;
	qcom,setb-gpios-dir =  <2 2 2 2 2 2 2 2 2 2 2 2 2 2 2 2 2 2>;
};

&vph_pwr_vreg {
	status = "ok";
};

&slim_msm {
	taiko_codec {
		qcom,cdc-reset-gpio = <&msmgpio 78 0>;
		qcom,cdc-micbias1-ext-cap;
		qcom,cdc-micbias2-ext-cap;
		qcom,cdc-micbias3-ext-cap;
		qcom,cdc-micbias4-ext-cap;

		/*
		 * Liquid has external spkrdrv supply. Give a dummy supply to
		 * make codec driver's happy.
		 */
		cdc-vdd-spkdrv-supply = <&vph_pwr_vreg>;
		qcom,cdc-vdd-spkdrv-voltage = <0 0>;
		qcom,cdc-vdd-spkdrv-current = <0>;

		qcom,cdc-on-demand-supplies = "cdc-vdd-spkdrv";
	};
	es325_gen_slim {
		compatible = "es325-gen";
		elemental-addr = [00 01 02 00 BE 02];

		es325-ldo-gpio = <&pm8941_gpios 11 0>;
		es325-reset-gpio = <&msmgpio 94 0>;
		es325-wakeup-gpio = <&msmgpio 85 0>;

		es325-mclk-clk = <&pm8941_clkdiv1>;
		es325-mclk-clk-freq = <9600000>;

		es325-slim-ifd = "es325-ifd";
		es325-slim-ifd-elemental-addr = [00 00 02 00 BE 02];
	};
};

